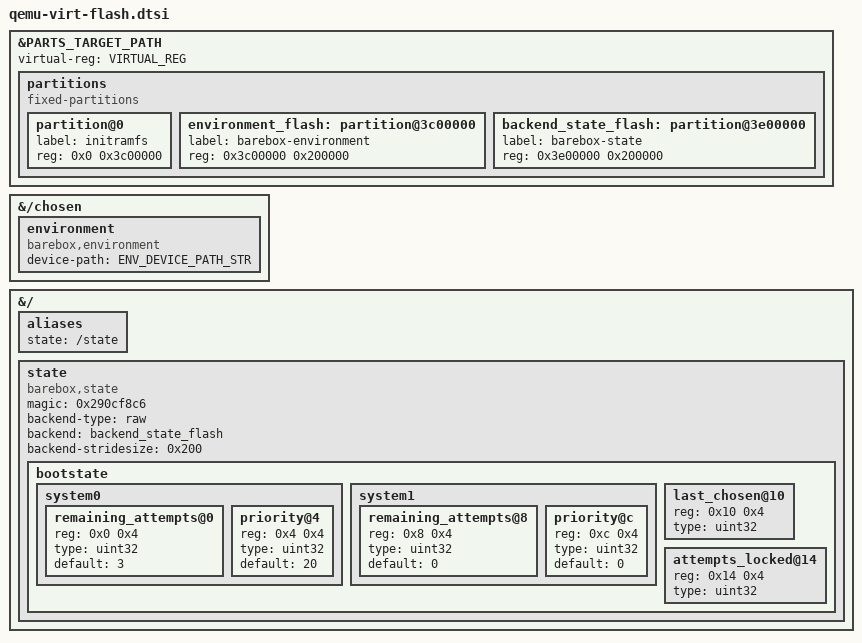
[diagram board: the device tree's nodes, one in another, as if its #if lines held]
/* SPDX-License-Identifier: GPL-2.0-only */

/dts-v1/;
/plugin/;

#include "qemu-virt-flash.h"

&{PARTS_TARGET_PATH} {
#ifdef VIRTUAL_REG
	virtual-reg = <VIRTUAL_REG>;
#endif
	partitions {
		compatible = "fixed-partitions";
		#address-cells = <1>;
		#size-cells = <1>;

		partition@0 {
			label = "initramfs";
			reg = <0x0 0x3c00000>;
		};

		environment_flash: partition@3c00000 {
			label = "barebox-environment";
			reg = <0x3c00000 0x200000>;
		};

		backend_state_flash: partition@3e00000 {
			label = "barebox-state";
			reg = <0x3e00000 0x200000>;
		};
	};
};

&{/chosen} {
	environment {
		compatible = "barebox,environment";
		device-path = ENV_DEVICE_PATH_STR;
	};
};

&{/} {
	aliases {
		state = "/state";
	};

	state {
		#address-cells = <1>;
		#size-cells = <1>;
		compatible = "barebox,state";
		magic = <0x290cf8c6>;
		backend-type = "raw";
		backend = < &backend_state_flash >;
		backend-stridesize = <0x200>;

		bootstate {
			#address-cells = <1>;
			#size-cells = <1>;

			system0 {
				#address-cells = <1>;
				#size-cells = <1>;

				remaining_attempts@0 {
					reg = <0x0 0x4>;
					type = "uint32";
					default = <3>;
				};

				priority@4 {
					reg = <0x4 0x4>;
					type = "uint32";
					default = <20>;
				};
			};

			system1 {
				#address-cells = <1>;
				#size-cells = <1>;

				remaining_attempts@8 {
					reg = <0x8 0x4>;
					type = "uint32";
					default = <0>;
				};

				priority@c {
					reg = <0xc 0x4>;
					type = "uint32";
					default = <0>;
				};
			};

			last_chosen@10 {
				reg = <0x10 0x4>;
				type = "uint32";
			};

			attempts_locked@14 {
				reg = <0x14 0x4>;
				type = "uint32";
			};
		};
	};
};

